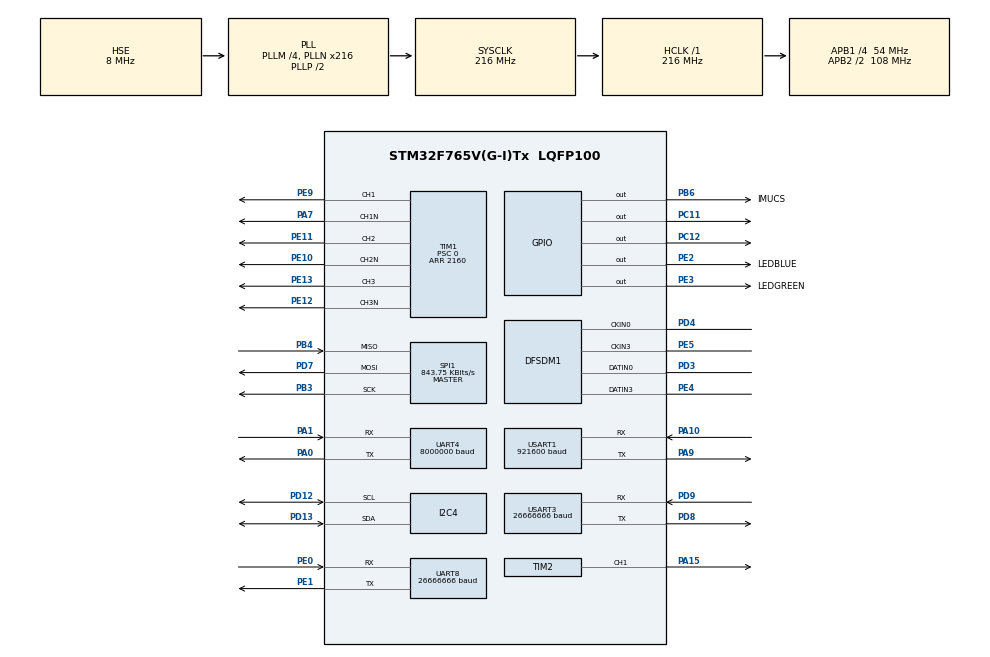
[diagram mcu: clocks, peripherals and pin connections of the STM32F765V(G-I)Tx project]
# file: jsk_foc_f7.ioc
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CORTEX_M7.ART_ACCLERATOR_ENABLE=1
CORTEX_M7.CPU_DCache=Enabled
CORTEX_M7.CPU_ICache=Enabled
CORTEX_M7.FlashInterface=AXI_Enabled
CORTEX_M7.PREFETCH_ENABLE=1
DFSDM1.DmaMode_reg_FIL0=ENABLE
DFSDM1.DmaMode_reg_FIL1=ENABLE
DFSDM1.FastMode_reg_FIL0=ENABLE
DFSDM1.FastMode_reg_FIL1=ENABLE
DFSDM1.FilterOrder_CH0=DFSDM_CHANNEL_SINC3_ORDER
DFSDM1.FilterOrder_CH3=DFSDM_CHANNEL_SINC3_ORDER
DFSDM1.Filter_regChannel_FIL0=DFSDM_CHANNEL_0
DFSDM1.Filter_regChannel_FIL1=DFSDM_CHANNEL_3
DFSDM1.Fosr_FIL0=256
DFSDM1.Fosr_FIL1=256
DFSDM1.Iosr_FIL0=2
DFSDM1.Iosr_FIL1=2
DFSDM1.Oversampling_CH0=1
DFSDM1.SincOrder_FIL0=DFSDM_FILTER_SINC3_ORDER
DFSDM1.SincOrder_FIL1=DFSDM_FILTER_SINC3_ORDER
DFSDM1.Type_spi_CH0=DFSDM_CHANNEL_SPI_RISING
DFSDM1.Type_spi_CH3=DFSDM_CHANNEL_SPI_RISING
Dma.DFSDM1_FLT0.1.Direction=DMA_PERIPH_TO_MEMORY
Dma.DFSDM1_FLT0.1.FIFOMode=DMA_FIFOMODE_DISABLE
Dma.DFSDM1_FLT0.1.Instance=DMA2_Stream0
Dma.DFSDM1_FLT0.1.MemDataAlignment=DMA_MDATAALIGN_WORD
Dma.DFSDM1_FLT0.1.MemInc=DMA_MINC_ENABLE
Dma.DFSDM1_FLT0.1.Mode=DMA_CIRCULAR
Dma.DFSDM1_FLT0.1.PeriphDataAlignment=DMA_PDATAALIGN_WORD
Dma.DFSDM1_FLT0.1.PeriphInc=DMA_PINC_DISABLE
Dma.DFSDM1_FLT0.1.Priority=DMA_PRIORITY_MEDIUM
Dma.DFSDM1_FLT1.2.Direction=DMA_PERIPH_TO_MEMORY
Dma.DFSDM1_FLT1.2.FIFOMode=DMA_FIFOMODE_DISABLE
Dma.DFSDM1_FLT1.2.Instance=DMA2_Stream1
Dma.DFSDM1_FLT1.2.MemDataAlignment=DMA_MDATAALIGN_WORD
Dma.DFSDM1_FLT1.2.MemInc=DMA_MINC_ENABLE
Dma.DFSDM1_FLT1.2.Mode=DMA_CIRCULAR
Dma.DFSDM1_FLT1.2.PeriphDataAlignment=DMA_PDATAALIGN_WORD
Dma.DFSDM1_FLT1.2.PeriphInc=DMA_PINC_DISABLE
Dma.DFSDM1_FLT1.2.Priority=DMA_PRIORITY_MEDIUM
Dma.Request0=USART1_RX
Dma.Request1=DFSDM1_FLT0
Dma.Request2=DFSDM1_FLT1
Dma.Request3=UART4_RX
Dma.Request4=USART1_TX
Dma.UART4_RX.3.Direction=DMA_PERIPH_TO_MEMORY
Dma.UART4_RX.3.FIFOMode=DMA_FIFOMODE_DISABLE
Dma.UART4_RX.3.Instance=DMA1_Stream2
Dma.UART4_RX.3.MemDataAlignment=DMA_MDATAALIGN_BYTE
Dma.UART4_RX.3.MemInc=DMA_MINC_ENABLE
Dma.UART4_RX.3.Mode=DMA_CIRCULAR
Dma.UART4_RX.3.PeriphDataAlignment=DMA_PDATAALIGN_BYTE
Dma.UART4_RX.3.PeriphInc=DMA_PINC_DISABLE
Dma.UART4_RX.3.Priority=DMA_PRIORITY_MEDIUM
Dma.USART1_RX.0.Direction=DMA_PERIPH_TO_MEMORY
Dma.USART1_RX.0.FIFOMode=DMA_FIFOMODE_ENABLE
Dma.USART1_RX.0.FIFOThreshold=DMA_FIFO_THRESHOLD_HALFFULL
Dma.USART1_RX.0.Instance=DMA2_Stream2
Dma.USART1_RX.0.MemBurst=DMA_MBURST_INC8
Dma.USART1_RX.0.MemDataAlignment=DMA_MDATAALIGN_BYTE
Dma.USART1_RX.0.MemInc=DMA_MINC_ENABLE
Dma.USART1_RX.0.Mode=DMA_CIRCULAR
Dma.USART1_RX.0.PeriphBurst=DMA_PBURST_SINGLE
Dma.USART1_RX.0.PeriphDataAlignment=DMA_PDATAALIGN_BYTE
Dma.USART1_RX.0.PeriphInc=DMA_PINC_DISABLE
Dma.USART1_RX.0.Priority=DMA_PRIORITY_MEDIUM
Dma.USART1_TX.4.Direction=DMA_MEMORY_TO_PERIPH
Dma.USART1_TX.4.FIFOMode=DMA_FIFOMODE_DISABLE
Dma.USART1_TX.4.Instance=DMA2_Stream7
Dma.USART1_TX.4.MemDataAlignment=DMA_MDATAALIGN_BYTE
Dma.USART1_TX.4.MemInc=DMA_MINC_ENABLE
Dma.USART1_TX.4.Mode=DMA_CIRCULAR
Dma.USART1_TX.4.PeriphDataAlignment=DMA_PDATAALIGN_BYTE
Dma.USART1_TX.4.PeriphInc=DMA_PINC_DISABLE
Dma.USART1_TX.4.Priority=DMA_PRIORITY_MEDIUM
FREERTOS.Mutexes01=buzzerMutex,Dynamic,NULL
FREERTOS.Queues01=buzzerQueue,1,uint16_t,NULL,Dynamic,NULL,NULL;rythmQueue,32,uint16_t,NULL,Dynamic,NULL,NULL;enchallQueue,1,ENCHD,NULL,Dynamic,NULL,NULL;shuntQueue,1,CURDATA,NULL,Dynamic,NULL,NULL;conresQueue,1,CONRES,NULL,Dynamic,NULL,NULL
FREERTOS.Tasks01=enchallTask,0,128,StartenchallTask,As weak,NULL,Dynamic,NULL,NULL;controlTask,1,128,StartcontrolTask,As weak,NULL,Dynamic,NULL,NULL;ledblueTask,-3,128,StartledblueTask,As weak,NULL,Dynamic,NULL,NULL;ledgreenTask,-3,128,StartledgreenTask,As weak,NULL,Dynamic,NULL,NULL;iwdgTask,-3,128,StartiwdgTask,As weak,NULL,Dynamic,NULL,NULL;buzzertoneTask,-3,128,StartbuzzertoneTask,As weak,NULL,Dynamic,NULL,NULL;buzzerrythmTask,-3,128,StartbuzzerrythmTask,As weak,NULL,Dynamic,NULL,NULL
FREERTOS.configUSE_TIMERS=0
I2C4.Timing=0x20404768
Mcu.Family=STM32F7
Mcu.Name=STM32F765V(G-I)Tx
Mcu.Package=LQFP100
NVIC.DMA1_Stream2_IRQn=true\:5\:0\:false\:false\:true\:true\:false
NVIC.DMA2_Stream0_IRQn=true\:5\:0\:false\:false\:true\:true\:false
NVIC.DMA2_Stream1_IRQn=true\:5\:0\:false\:false\:true\:true\:false
NVIC.DMA2_Stream2_IRQn=true\:5\:0\:false\:false\:true\:true\:false
NVIC.DMA2_Stream7_IRQn=true\:5\:0\:false\:false\:true\:true\:false
NVIC.PriorityGroup=NVIC_PRIORITYGROUP_4
NVIC.TIM4_IRQn=true\:0\:0\:false\:false\:true\:false\:false
NVIC.TimeBase=TIM4_IRQn
NVIC.TimeBaseIP=TIM4
PA0/WKUP.Mode=Asynchronous
PA0/WKUP.Signal=UART4_TX
PA1.Mode=Asynchronous
PA1.Signal=UART4_RX
PA10.Mode=Asynchronous
PA10.Signal=USART1_RX
PA13.Mode=Serial_Wire
PA13.Signal=SYS_JTMS-SWDIO
PA14.Mode=Serial_Wire
PA14.Signal=SYS_JTCK-SWCLK
PA15.GPIO_Speed=GPIO_SPEED_FREQ_MEDIUM
PA15.Signal=S_TIM2_CH1_ETR
PA7.Mode=PWM Generation1 CH1 CH1N
PA7.Signal=TIM1_CH1N
PA9.Mode=Asynchronous
PA9.Signal=USART1_TX
PB3.Mode=Full_Duplex_Master
PB3.Signal=SPI1_SCK
PB4.Mode=Full_Duplex_Master
PB4.Signal=SPI1_MISO
PB6.GPIO_FM6=__NULL
PB6.GPIO_Label=IMUCS
PB6.GPIO_PuPd=GPIO_PULLUP
PB6.GPIO_Speed=GPIO_SPEED_FREQ_MEDIUM
PB6.Signal=GPIO_Output
PC11.Signal=GPIO_Output
PC12.GPIO_PuPd=GPIO_PULLDOWN
PC12.Signal=GPIO_Output
PD12.Mode=I2C
PD12.Signal=I2C4_SCL
PD13.Mode=I2C
PD13.Signal=I2C4_SDA
PD3.Signal=S_DATAIN0DFSDM1
PD4.Signal=S_CKIN0DFSDM1
PD7.Mode=Full_Duplex_Master
PD7.Signal=SPI1_MOSI
PD8.Mode=Asynchronous
PD8.Signal=USART3_TX
PD9.Mode=Asynchronous
PD9.Signal=USART3_RX
PE0.Mode=Asynchronous
PE0.Signal=UART8_RX
PE1.Mode=Asynchronous
PE1.Signal=UART8_TX
PE10.Mode=PWM Generation2 CH2 CH2N
PE10.Signal=TIM1_CH2N
PE11.Signal=S_TIM1_CH2
PE12.Mode=PWM Generation3 CH3 CH3N
PE12.Signal=TIM1_CH3N
PE13.Signal=S_TIM1_CH3
PE2.GPIO_Label=LEDBLUE
PE2.GPIO_ModeDefaultOutputPP=GPIO_MODE_OUTPUT_OD
PE2.Signal=GPIO_Output
PE3.GPIO_Label=LEDGREEN
PE3.GPIO_ModeDefaultOutputPP=GPIO_MODE_OUTPUT_OD
PE3.Signal=GPIO_Output
PE4.Signal=S_DATAIN3DFSDM1
PE5.Signal=S_CKIN3DFSDM1
PE9.Signal=S_TIM1_CH1
PH0/OSC_IN.Mode=HSE-External-Oscillator
PH0/OSC_IN.Signal=RCC_OSC_IN
PH1/OSC_OUT.Mode=HSE-External-Oscillator
PH1/OSC_OUT.Signal=RCC_OSC_OUT
ProjectManager.HeapSize=0x200
ProjectManager.StackSize=0x400
ProjectManager.TargetToolchain=TrueSTUDIO
RCC.AHBFreq_Value=216000000
RCC.APB1CLKDivider=RCC_HCLK_DIV4
RCC.APB1Freq_Value=54000000
RCC.APB1TimFreq_Value=108000000
RCC.APB2CLKDivider=RCC_HCLK_DIV2
RCC.APB2Freq_Value=108000000
RCC.APB2TimFreq_Value=216000000
RCC.CortexFreq_Value=216000000
RCC.HCLKFreq_Value=216000000
RCC.HSE_VALUE=8000000
RCC.HSI_VALUE=16000000
RCC.LSE_VALUE=32768
RCC.PLLM=4
RCC.PLLN=216
RCC.PLLQ=4
RCC.PLLSourceVirtual=RCC_PLLSOURCE_HSE
RCC.RCC_MCO1Source=RCC_MCO1SOURCE_PLLCLK
RCC.RCC_MCODiv1=RCC_MCODIV_4
RCC.RCC_TIM_PRescaler_Selection=RCC_TIMPRES_DESACTIVATED
RCC.SYSCLKFreq_VALUE=216000000
RCC.SYSCLKSource=RCC_SYSCLKSOURCE_PLLCLK
RCC.UART4CLockSelection=RCC_UART4CLKSOURCE_SYSCLK
RCC.UART8CLockSelection=RCC_UART8CLKSOURCE_SYSCLK
RCC.USART1CLockSelection=RCC_USART1CLKSOURCE_SYSCLK
RCC.USART3CLockSelection=RCC_USART3CLKSOURCE_SYSCLK
RCC.USBFreq_Value=108000000
RCC.VCOOutputFreq_Value=432000000
SH.S_CKIN0DFSDM1.0=DFSDM1_CKIN0,PDM_SPI_input_from_ch0_and_external_clock
SH.S_CKIN3DFSDM1.0=DFSDM1_CKIN3,PDM_SPI_input_from_ch3_and_external_clock
SH.S_DATAIN0DFSDM1.0=DFSDM1_DATIN0,PDM_SPI_input_from_ch0_and_external_clock
SH.S_DATAIN3DFSDM1.0=DFSDM1_DATIN3,PDM_SPI_input_from_ch3_and_external_clock
SH.S_TIM1_CH1.0=TIM1_CH1,PWM Generation1 CH1 CH1N
SH.S_TIM1_CH2.0=TIM1_CH2,PWM Generation2 CH2 CH2N
SH.S_TIM1_CH3.0=TIM1_CH3,PWM Generation3 CH3 CH3N
SH.S_TIM2_CH1_ETR.0=TIM2_CH1,PWM Generation1 CH1
SPI1.BaudRatePrescaler=SPI_BAUDRATEPRESCALER_128
SPI1.CalculateBaudRate=843.75 KBits/s
SPI1.DataSize=SPI_DATASIZE_8BIT
SPI1.Direction=SPI_DIRECTION_2LINES
SPI1.Mode=SPI_MODE_MASTER
SPI1.VirtualType=VM_MASTER
TIM1.AutoReloadPreload=TIM_AUTORELOAD_PRELOAD_DISABLE
TIM1.AutomaticOutput=TIM_AUTOMATICOUTPUT_ENABLE
TIM1.BreakState=TIM_BREAK_DISABLE
TIM1.Channel-PWM\ Generation1\ CH1\ CH1N=TIM_CHANNEL_1
TIM1.Channel-PWM\ Generation2\ CH2\ CH2N=TIM_CHANNEL_2
TIM1.Channel-PWM\ Generation3\ CH3\ CH3N=TIM_CHANNEL_3
TIM1.ClockDivision=TIM_CLOCKDIVISION_DIV1
TIM1.CounterMode=TIM_COUNTERMODE_CENTERALIGNED1
TIM1.DeadTime=45
TIM1.OCMode_PWM-PWM\ Generation1\ CH1\ CH1N=TIM_OCMODE_PWM1
TIM1.OCMode_PWM-PWM\ Generation2\ CH2\ CH2N=TIM_OCMODE_PWM1
TIM1.OCMode_PWM-PWM\ Generation3\ CH3\ CH3N=TIM_OCMODE_PWM1
TIM1.OCNPolarity_1=TIM_OCNPOLARITY_HIGH
TIM1.Period=2160
TIM1.Prescaler=0
TIM1.Pulse-PWM\ Generation1\ CH1\ CH1N=580
TIM1.RepetitionCounter=0
TIM1.SourceBRKDFSDM1=TIM_BREAKINPUTSOURCE_DISABLE
TIM2.AutoReloadPreload=TIM_AUTORELOAD_PRELOAD_ENABLE
TIM2.Channel-PWM\ Generation1\ CH1=TIM_CHANNEL_1
TIM2.ClockDivision=TIM_CLOCKDIVISION_DIV1
TIM2.OCMode_PWM-PWM\ Generation1\ CH1=TIM_OCMODE_PWM1
TIM2.Period=50000
TIM2.Prescaler=107
TIM2.Pulse-PWM\ Generation1\ CH1=0
TIM2.TIM_MasterOutputTrigger=TIM_TRGO_RESET
TIM3.Period=50000
TIM3.Prescaler=107
UART4.BaudRate=8000000
UART4.DMADisableonRxErrorParam=UART_ADVFEATURE_DMA_DISABLEONRXERROR
UART4.MSBFirstParam=UART_ADVFEATURE_MSBFIRST_ENABLE
UART4.Mode=MODE_RX
UART4.OverSampling=UART_OVERSAMPLING_16
UART4.OverrunDisableParam=UART_ADVFEATURE_OVERRUN_DISABLE
UART4.WordLength=WORDLENGTH_8B
UART8.BaudRate=26666666
UART8.OverSampling=UART_OVERSAMPLING_8
UART8.WordLength=WORDLENGTH_8B
USART1.BaudRate=921600
USART1.OverrunDisableParam=ADVFEATURE_OVERRUN_ENABLE
USART1.VirtualMode-Asynchronous=VM_ASYNC
USART1.WordLength=WORDLENGTH_8B
USART3.BaudRate=26666666
USART3.OverSampling=UART_OVERSAMPLING_8
USART3.VirtualMode-Asynchronous=VM_ASYNC
USART3.WordLength=WORDLENGTH_8B
VP_FREERTOS_VS_ENABLE.Mode=Enabled
VP_SYS_VS_tim4.Mode=TIM4
VP_TIM1_VS_ClockSourceINT.Mode=Internal
VP_TIM2_VS_ClockSourceINT.Mode=Internal
VP_TIM3_VS_ClockSourceINT.Mode=Internal
board=jsk_foc_f7

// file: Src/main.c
/* USER CODE BEGIN Header */
/**
  ******************************************************************************
  * @file           : main.c
  * @brief          : Main program body
  ******************************************************************************
  * This notice applies to any and all portions of this file
  * that are not between comment pairs USER CODE BEGIN and
  * USER CODE END. Other portions of this file, whether
  * inserted by the user or by software development tools
  * are owned by their respective copyright owners.
  *
  * Copyright (c) 2018 STMicroelectronics International N.V.
  * All rights reserved.
  *
  * Redistribution and use in source and binary forms, with or without
  * modification, are permitted, provided that the following conditions are met:
  *
  * 1. Redistribution of source code must retain the above copyright notice,
  *    this list of conditions and the following disclaimer.
  * 2. Redistributions in binary form must reproduce the above copyright notice,
  *    this list of conditions and the following disclaimer in the documentation
  *    and/or other materials provided with the distribution.
  * 3. Neither the name of STMicroelectronics nor the names of other
  *    contributors to this software may be used to endorse or promote products
  *    derived from this software without specific written permission.
  * 4. This software, including modifications and/or derivative works of this
  *    software, must execute solely and exclusively on microcontroller or
  *    microprocessor devices manufactured by or for STMicroelectronics.
  * 5. Redistribution and use of this software other than as permitted under
  *    this license is void and will automatically terminate your rights under
  *    this license.
  *
  * THIS SOFTWARE IS PROVIDED BY STMICROELECTRONICS AND CONTRIBUTORS "AS IS"
  * AND ANY EXPRESS, IMPLIED OR STATUTORY WARRANTIES, INCLUDING, BUT NOT
  * LIMITED TO, THE IMPLIED WARRANTIES OF MERCHANTABILITY, FITNESS FOR A
  * PARTICULAR PURPOSE AND NON-INFRINGEMENT OF THIRD PARTY INTELLECTUAL PROPERTY
  * RIGHTS ARE DISCLAIMED TO THE FULLEST EXTENT PERMITTED BY LAW. IN NO EVENT
  * SHALL STMICROELECTRONICS OR CONTRIBUTORS BE LIABLE FOR ANY DIRECT, INDIRECT,
  * INCIDENTAL, SPECIAL, EXEMPLARY, OR CONSEQUENTIAL DAMAGES (INCLUDING, BUT NOT
  * LIMITED TO, PROCUREMENT OF SUBSTITUTE GOODS OR SERVICES; LOSS OF USE, DATA,
  * OR PROFITS; OR BUSINESS INTERRUPTION) HOWEVER CAUSED AND ON ANY THEORY OF
  * LIABILITY, WHETHER IN CONTRACT, STRICT LIABILITY, OR TORT (INCLUDING
  * NEGLIGENCE OR OTHERWISE) ARISING IN ANY WAY OUT OF THE USE OF THIS SOFTWARE,
  * EVEN IF ADVISED OF THE POSSIBILITY OF SUCH DAMAGE.
  *
  ******************************************************************************
  */
/* USER CODE END Header */

#include "main.h"
#include "cmsis_os.h"
#include "dfsdm.h"
#include "dma.h"
#include "i2c.h"
#include "spi.h"
#include "tim.h"
#include "usart.h"
#include "usb_otg.h"
#include "gpio.h"

/* USER CODE BEGIN PV */
/* Private variables ---------------------------------------------------------*/

/* USER CODE END PV */

void SystemClock_Config(void);
void MX_FREERTOS_Init(void);
/* USER CODE BEGIN PFP */
/* Private function prototypes -----------------------------------------------*/

/* USER CODE END PFP */

int main(void)
{

  /* Enable I-Cache---------------------------------------------------------*/
  SCB_EnableICache();

  /* Enable D-Cache---------------------------------------------------------*/
  SCB_EnableDCache();

  /* MCU Configuration--------------------------------------------------------*/

  /* Reset of all peripherals, Initializes the Flash interface and the Systick. */
  HAL_Init();

  /* Configure the system clock */
  SystemClock_Config();

  /* Initialize all configured peripherals */
  MX_GPIO_Init();
  MX_DMA_Init();
  MX_DFSDM1_Init();
  MX_I2C4_Init();
  MX_SPI1_Init();
  MX_TIM1_Init();
  MX_UART4_Init();
  MX_UART8_Init();
  MX_USART1_UART_Init();
  MX_USART3_UART_Init();
//  MX_USB_OTG_HS_PCD_Init();
  MX_TIM2_Init();
  MX_TIM3_Init();
  /* USER CODE BEGIN 2 */
  //system initialization
  SystemInitialization();
  /* USER CODE END 2 */

  /* Call init function for freertos objects (in freertos.c) */
  MX_FREERTOS_Init();

  /* Start scheduler */
  osKernelStart();

  /* We should never get here as control is now taken by the scheduler */

  /* Infinite loop */
  while (1)
  {

  }
}

void SystemClock_Config(void)
{
  RCC_OscInitTypeDef RCC_OscInitStruct = {0};
  RCC_ClkInitTypeDef RCC_ClkInitStruct = {0};
  RCC_PeriphCLKInitTypeDef PeriphClkInitStruct = {0};

  /**Configure the main internal regulator output voltage
  */
  __HAL_RCC_PWR_CLK_ENABLE();
  __HAL_PWR_VOLTAGESCALING_CONFIG(PWR_REGULATOR_VOLTAGE_SCALE1);
  /**Initializes the CPU, AHB and APB busses clocks
  */
  RCC_OscInitStruct.OscillatorType = RCC_OSCILLATORTYPE_HSE;
  RCC_OscInitStruct.HSEState = RCC_HSE_ON;
  RCC_OscInitStruct.PLL.PLLState = RCC_PLL_ON;
  RCC_OscInitStruct.PLL.PLLSource = RCC_PLLSOURCE_HSE;
  RCC_OscInitStruct.PLL.PLLM = 4;
  RCC_OscInitStruct.PLL.PLLN = 216;
  RCC_OscInitStruct.PLL.PLLP = RCC_PLLP_DIV2;
  RCC_OscInitStruct.PLL.PLLQ = 4;
  if (HAL_RCC_OscConfig(&RCC_OscInitStruct) != HAL_OK)
  {
    Error_Handler();
  }
  /**Activate the Over-Drive mode
  */
  if (HAL_PWREx_EnableOverDrive() != HAL_OK)
  {
    Error_Handler();
  }
  /**Initializes the CPU, AHB and APB busses clocks
  */
  RCC_ClkInitStruct.ClockType = RCC_CLOCKTYPE_HCLK|RCC_CLOCKTYPE_SYSCLK
                              |RCC_CLOCKTYPE_PCLK1|RCC_CLOCKTYPE_PCLK2;
  RCC_ClkInitStruct.SYSCLKSource = RCC_SYSCLKSOURCE_PLLCLK;
  RCC_ClkInitStruct.AHBCLKDivider = RCC_SYSCLK_DIV1;
  RCC_ClkInitStruct.APB1CLKDivider = RCC_HCLK_DIV4;
  RCC_ClkInitStruct.APB2CLKDivider = RCC_HCLK_DIV2;

  if (HAL_RCC_ClockConfig(&RCC_ClkInitStruct, FLASH_LATENCY_7) != HAL_OK)
  {
    Error_Handler();
  }
  PeriphClkInitStruct.PeriphClockSelection = RCC_PERIPHCLK_DFSDM1|RCC_PERIPHCLK_USART1
                              |RCC_PERIPHCLK_USART3|RCC_PERIPHCLK_UART4
                              |RCC_PERIPHCLK_UART8|RCC_PERIPHCLK_I2C4;
  PeriphClkInitStruct.Usart1ClockSelection = RCC_USART1CLKSOURCE_SYSCLK;
  PeriphClkInitStruct.Usart3ClockSelection = RCC_USART3CLKSOURCE_SYSCLK;
  PeriphClkInitStruct.Uart4ClockSelection = RCC_UART4CLKSOURCE_SYSCLK;
  PeriphClkInitStruct.Uart8ClockSelection = RCC_UART8CLKSOURCE_SYSCLK;
  PeriphClkInitStruct.I2c4ClockSelection = RCC_I2C4CLKSOURCE_PCLK1;
  PeriphClkInitStruct.Dfsdm1ClockSelection = RCC_DFSDM1CLKSOURCE_PCLK;
  if (HAL_RCCEx_PeriphCLKConfig(&PeriphClkInitStruct) != HAL_OK)
  {
    Error_Handler();
  }
}

void HAL_TIM_PeriodElapsedCallback(TIM_HandleTypeDef *htim)
{
  if (htim->Instance == TIM4) {
    HAL_IncTick();
  }
}

void Error_Handler(void)
{
  while(1)
  {
  }
}

/************************ (C) COPYRIGHT STMicroelectronics *****END OF FILE****/

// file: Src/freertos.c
/* USER CODE BEGIN Header */
/**
  ******************************************************************************
  * File Name          : freertos.c
  * Description        : Code for freertos applications
  ******************************************************************************
  * This notice applies to any and all portions of this file
  * that are not between comment pairs USER CODE BEGIN and
  * USER CODE END. Other portions of this file, whether
  * inserted by the user or by software development tools
  * are owned by their respective copyright owners.
  *
  * Copyright (c) 2018 STMicroelectronics International N.V.
  * All rights reserved.
  *
  * Redistribution and use in source and binary forms, with or without
  * modification, are permitted, provided that the following conditions are met:
  *
  * 1. Redistribution of source code must retain the above copyright notice,
  *    this list of conditions and the following disclaimer.
  * 2. Redistributions in binary form must reproduce the above copyright notice,
  *    this list of conditions and the following disclaimer in the documentation
  *    and/or other materials provided with the distribution.
  * 3. Neither the name of STMicroelectronics nor the names of other
  *    contributors to this software may be used to endorse or promote products
  *    derived from this software without specific written permission.
  * 4. This software, including modifications and/or derivative works of this
  *    software, must execute solely and exclusively on microcontroller or
  *    microprocessor devices manufactured by or for STMicroelectronics.
  * 5. Redistribution and use of this software other than as permitted under
  *    this license is void and will automatically terminate your rights under
  *    this license.
  *
  * THIS SOFTWARE IS PROVIDED BY STMICROELECTRONICS AND CONTRIBUTORS "AS IS"
  * AND ANY EXPRESS, IMPLIED OR STATUTORY WARRANTIES, INCLUDING, BUT NOT
  * LIMITED TO, THE IMPLIED WARRANTIES OF MERCHANTABILITY, FITNESS FOR A
  * PARTICULAR PURPOSE AND NON-INFRINGEMENT OF THIRD PARTY INTELLECTUAL PROPERTY
  * RIGHTS ARE DISCLAIMED TO THE FULLEST EXTENT PERMITTED BY LAW. IN NO EVENT
  * SHALL STMICROELECTRONICS OR CONTRIBUTORS BE LIABLE FOR ANY DIRECT, INDIRECT,
  * INCIDENTAL, SPECIAL, EXEMPLARY, OR CONSEQUENTIAL DAMAGES (INCLUDING, BUT NOT
  * LIMITED TO, PROCUREMENT OF SUBSTITUTE GOODS OR SERVICES; LOSS OF USE, DATA,
  * OR PROFITS; OR BUSINESS INTERRUPTION) HOWEVER CAUSED AND ON ANY THEORY OF
  * LIABILITY, WHETHER IN CONTRACT, STRICT LIABILITY, OR TORT (INCLUDING
  * NEGLIGENCE OR OTHERWISE) ARISING IN ANY WAY OUT OF THE USE OF THIS SOFTWARE,
  * EVEN IF ADVISED OF THE POSSIBILITY OF SUCH DAMAGE.
  *
  ******************************************************************************
  */
/* USER CODE END Header */

#include "FreeRTOS.h"
#include "task.h"
#include "main.h"
#include "cmsis_os.h"

osThreadId enchallTaskHandle;
osThreadId controlTaskHandle;
osThreadId ledblueTaskHandle;
osThreadId ledgreenTaskHandle;
osThreadId iwdgTaskHandle;
osThreadId buzzertoneTaskHandle;
osThreadId buzzerrythmTaskHandle;
osMessageQId buzzerQueueHandle;
osMessageQId rythmQueueHandle;
osMessageQId enchallQueueHandle;
osMessageQId shuntQueueHandle;
osMessageQId conresQueueHandle;
osMutexId buzzerMutexHandle;

void StartenchallTask(void const * argument);
void StartcontrolTask(void const * argument);
void StartledblueTask(void const * argument);
void StartledgreenTask(void const * argument);
void StartiwdgTask(void const * argument);
void StartbuzzertoneTask(void const * argument);
void StartbuzzerrythmTask(void const * argument);

void MX_FREERTOS_Init(void); /* (MISRA C 2004 rule 8.1) */

void MX_FREERTOS_Init(void) {

  /* Create the mutex(es) */
  /* definition and creation of buzzerMutex */
  osMutexDef(buzzerMutex);
  buzzerMutexHandle = osMutexCreate(osMutex(buzzerMutex));

  /* Create the thread(s) */
  /* definition and creation of enchallTask */
  osThreadDef(enchallTask, StartenchallTask, osPriorityNormal, 0, 1280);
  enchallTaskHandle = osThreadCreate(osThread(enchallTask), NULL);

  /* definition and creation of controlTask */
  osThreadDef(controlTask, StartcontrolTask, osPriorityAboveNormal, 0, 128);
  controlTaskHandle = osThreadCreate(osThread(controlTask), NULL);

  /* definition and creation of ledblueTask */
  osThreadDef(ledblueTask, StartledblueTask, osPriorityIdle, 0, 128);
  ledblueTaskHandle = osThreadCreate(osThread(ledblueTask), NULL);

  /* definition and creation of ledgreenTask */
  osThreadDef(ledgreenTask, StartledgreenTask, osPriorityIdle, 0, 128);
  ledgreenTaskHandle = osThreadCreate(osThread(ledgreenTask), NULL);

  /* definition and creation of iwdgTask */
  osThreadDef(iwdgTask, StartiwdgTask, osPriorityIdle, 0, 128);
  iwdgTaskHandle = osThreadCreate(osThread(iwdgTask), NULL);

  /* definition and creation of buzzertoneTask */
  osThreadDef(buzzertoneTask, StartbuzzertoneTask, osPriorityIdle, 0, 128);
  buzzertoneTaskHandle = osThreadCreate(osThread(buzzertoneTask), NULL);

  /* definition and creation of buzzerrythmTask */
  osThreadDef(buzzerrythmTask, StartbuzzerrythmTask, osPriorityIdle, 0, 128);
  buzzerrythmTaskHandle = osThreadCreate(osThread(buzzerrythmTask), NULL);

  /* Create the queue(s) */
  /* definition and creation of buzzerQueue */
  osMessageQDef(buzzerQueue, 1, uint16_t);
  buzzerQueueHandle = osMessageCreate(osMessageQ(buzzerQueue), NULL);

  /* definition and creation of rythmQueue */
  osMessageQDef(rythmQueue, 32, uint16_t);
  rythmQueueHandle = osMessageCreate(osMessageQ(rythmQueue), NULL);

  /* definition and creation of enchallQueue */
  osMessageQDef(enchallQueue, 1, ENCHD);
  enchallQueueHandle = osMessageCreate(osMessageQ(enchallQueue), NULL);

  /* definition and creation of shuntQueue */
  osMessageQDef(shuntQueue, 1, CURDATA);
  shuntQueueHandle = osMessageCreate(osMessageQ(shuntQueue), NULL);

  /* definition and creation of conresQueue */
  osMessageQDef(conresQueue, 1, CONRES);
  conresQueueHandle = osMessageCreate(osMessageQ(conresQueue), NULL);

}

__weak void StartenchallTask(void const * argument)
{

  for(;;)
  {
    osDelay(1);
  }
}

__weak void StartcontrolTask(void const * argument)
{
  for(;;)
  {
    osDelay(1);
  }
}

__weak void StartledblueTask(void const * argument)
{
  for(;;)
  {
    osDelay(1);
  }
}

__weak void StartledgreenTask(void const * argument)
{
  for(;;)
  {
    osDelay(1);
  }
}

__weak void StartiwdgTask(void const * argument)
{
  for(;;)
  {
    osDelay(1);
  }
}

__weak void StartbuzzertoneTask(void const * argument)
{
  for(;;)
  {
    osDelay(1);
  }
}

__weak void StartbuzzerrythmTask(void const * argument)
{
  for(;;)
  {
    osDelay(1);
  }
}

/************************ (C) COPYRIGHT STMicroelectronics *****END OF FILE****/
